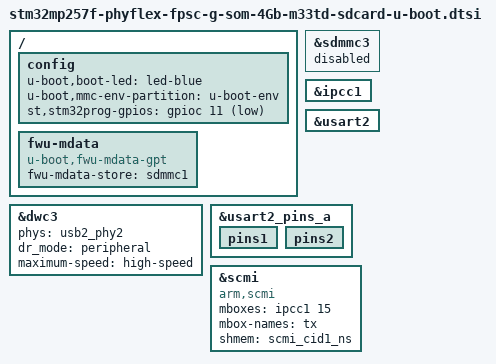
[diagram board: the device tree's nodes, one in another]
// SPDX-License-Identifier: (GPL-2.0+ OR BSD-3-Clause)
/*
 * Copyright (C) PHYTEC GmbH 2025 - All Rights Reserved
 * Author: Christophe PARANT <c.parant@phytec.fr>,
 *         Nicolas Raimundo <n.raimundo@phytec.fr>.
 */

#include "stm32mp25-u-boot.dtsi"

/ {
	config {
		u-boot,boot-led = "led-blue";
		u-boot,mmc-env-partition = "u-boot-env";
		st,stm32prog-gpios = <&gpioc 11 (GPIO_ACTIVE_LOW | GPIO_PULL_UP)>;
	};

	fwu-mdata {
		compatible = "u-boot,fwu-mdata-gpt";
		fwu-mdata-store = <&sdmmc1>;
	};
};

&dwc3 {
	phys = <&usb2_phy2>;
	phy-names = "usb2-phy";
	dr_mode = "peripheral";
	maximum-speed = "high-speed";
	/delete-node/ port;
};

&sdmmc3 {
	status = "disabled";
};

&ipcc1 {
       bootph-all;
       /delete-property/ clocks;
       status = "okay";
};

&usart2 {
	bootph-all;
};

&usart2_pins_a {
	bootph-all;
	pins1 {
		bootph-all;
	};
	pins2 {
		bootph-all;
	};
};

&scmi {
	compatible = "arm,scmi";
	#address-cells = <1>;
	#size-cells = <0>;
	mboxes = <&ipcc1 15>;
	mbox-names = "tx";
	shmem = <&scmi_cid1_ns>;
	/delete-property/ linaro,optee-channel-id;
};
